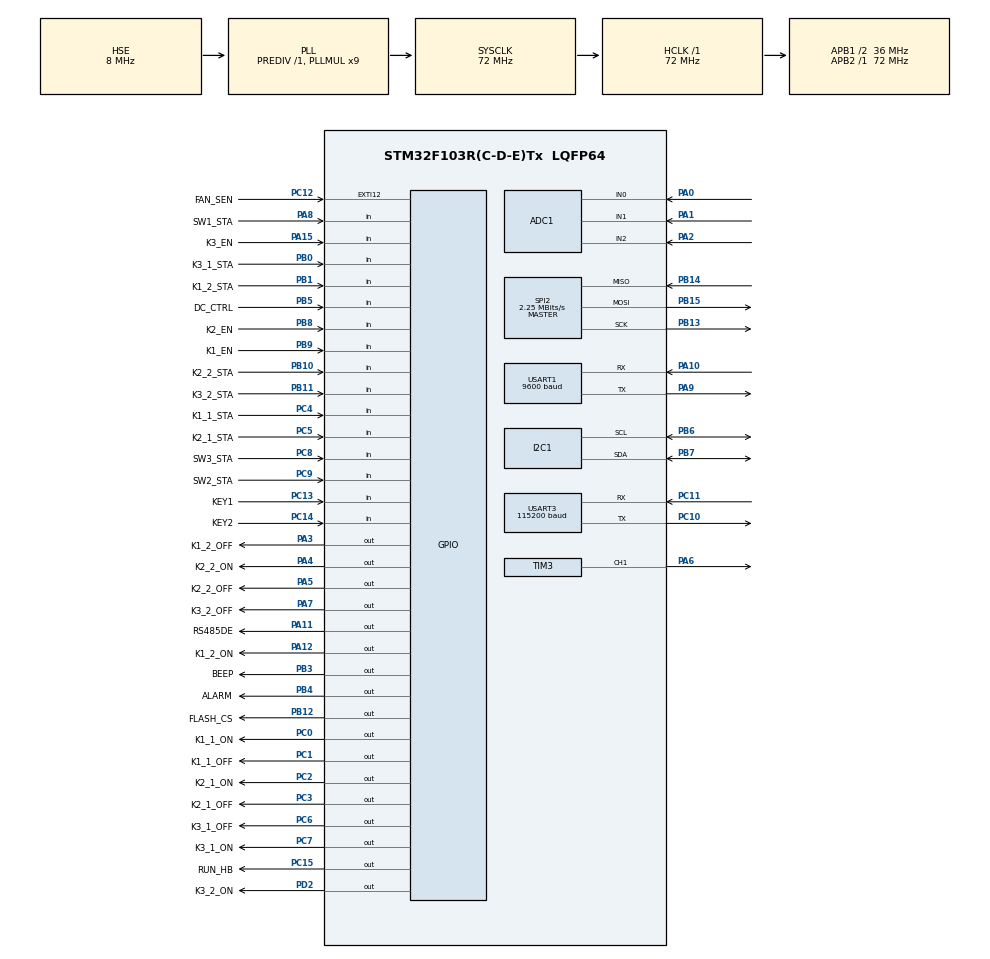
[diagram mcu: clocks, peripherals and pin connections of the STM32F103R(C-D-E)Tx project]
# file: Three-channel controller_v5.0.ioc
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ADC1.Channel-1\#ChannelRegularConversion=ADC_CHANNEL_1
ADC1.Channel-2\#ChannelRegularConversion=ADC_CHANNEL_2
ADC1.ContinuousConvMode=ENABLE
ADC1.DiscontinuousConvMode=DISABLE
ADC1.NbrOfConversion=3
ADC1.NbrOfConversionFlag=1
ADC1.Rank-1\#ChannelRegularConversion=2
ADC1.Rank-2\#ChannelRegularConversion=3
ADC1.SamplingTime-0\#ChannelRegularConversion=ADC_SAMPLETIME_55CYCLES_5
ADC1.SamplingTime-1\#ChannelRegularConversion=ADC_SAMPLETIME_55CYCLES_5
ADC1.SamplingTime-2\#ChannelRegularConversion=ADC_SAMPLETIME_55CYCLES_5
ADC1.master=1
Dma.ADC1.0.Direction=DMA_PERIPH_TO_MEMORY
Dma.ADC1.0.Instance=DMA1_Channel1
Dma.ADC1.0.MemDataAlignment=DMA_MDATAALIGN_HALFWORD
Dma.ADC1.0.MemInc=DMA_MINC_ENABLE
Dma.ADC1.0.Mode=DMA_CIRCULAR
Dma.ADC1.0.PeriphDataAlignment=DMA_PDATAALIGN_HALFWORD
Dma.ADC1.0.PeriphInc=DMA_PINC_DISABLE
Dma.ADC1.0.Priority=DMA_PRIORITY_LOW
Dma.Request0=ADC1
Mcu.Family=STM32F1
Mcu.Name=STM32F103R(C-D-E)Tx
Mcu.Package=LQFP64
NVIC.ADC1_2_IRQn=true\:5\:0\:true\:false\:true\:true\:true\:true
NVIC.EXTI15_10_IRQn=true\:4\:0\:true\:false\:true\:true\:true\:true
NVIC.PriorityGroup=NVIC_PRIORITYGROUP_4
PA0-WKUP.GPIO_Mode=GPIO_MODE_ANALOG
PA0-WKUP.Signal=ADCx_IN0
PA1.GPIO_Mode=GPIO_MODE_ANALOG
PA1.Signal=ADCx_IN1
PA10.Mode=Asynchronous
PA10.Signal=USART1_RX
PA11.GPIO_Label=RS485DE
PA11.GPIO_PuPd=GPIO_PULLDOWN
PA11.GPIO_Speed=GPIO_SPEED_FREQ_HIGH
PA11.PinState=GPIO_PIN_RESET
PA11.Signal=GPIO_Output
PA12.GPIO_Label=K1_2_ON
PA12.GPIO_PuPd=GPIO_PULLUP
PA12.GPIO_Speed=GPIO_SPEED_FREQ_HIGH
PA12.PinState=GPIO_PIN_SET
PA12.Signal=GPIO_Output
PA13.Mode=Serial_Wire
PA13.Signal=SYS_JTMS-SWDIO
PA14.Mode=Serial_Wire
PA14.Signal=SYS_JTCK-SWCLK
PA15.GPIO_Label=K3_EN
PA15.GPIO_PuPd=GPIO_PULLUP
PA15.Signal=GPIO_Input
PA2.GPIO_Mode=GPIO_MODE_ANALOG
PA2.Signal=ADCx_IN2
PA3.GPIO_Label=K1_2_OFF
PA3.GPIO_PuPd=GPIO_PULLUP
PA3.GPIO_Speed=GPIO_SPEED_FREQ_HIGH
PA3.PinState=GPIO_PIN_SET
PA3.Signal=GPIO_Output
PA4.GPIO_Label=K2_2_ON
PA4.GPIO_PuPd=GPIO_PULLUP
PA4.GPIO_Speed=GPIO_SPEED_FREQ_HIGH
PA4.PinState=GPIO_PIN_SET
PA4.Signal=GPIO_Output
PA5.GPIO_Label=K2_2_OFF
PA5.GPIO_PuPd=GPIO_PULLUP
PA5.GPIO_Speed=GPIO_SPEED_FREQ_HIGH
PA5.PinState=GPIO_PIN_SET
PA5.Signal=GPIO_Output
PA6.Signal=S_TIM3_CH1
PA7.GPIO_Label=K3_2_OFF
PA7.GPIO_PuPd=GPIO_PULLUP
PA7.GPIO_Speed=GPIO_SPEED_FREQ_HIGH
PA7.PinState=GPIO_PIN_SET
PA7.Signal=GPIO_Output
PA8.GPIO_Label=SW1_STA
PA8.GPIO_PuPd=GPIO_PULLDOWN
PA8.Signal=GPIO_Input
PA9.Mode=Asynchronous
PA9.Signal=USART1_TX
PB0.GPIO_Label=K3_1_STA
PB0.GPIO_PuPd=GPIO_PULLDOWN
PB0.Signal=GPIO_Input
PB1.GPIO_Label=K1_2_STA
PB1.GPIO_PuPd=GPIO_PULLDOWN
PB1.Signal=GPIO_Input
PB10.GPIO_Label=K2_2_STA
PB10.GPIO_PuPd=GPIO_PULLDOWN
PB10.Signal=GPIO_Input
PB11.GPIO_Label=K3_2_STA
PB11.GPIO_PuPd=GPIO_PULLDOWN
PB11.Signal=GPIO_Input
PB12.GPIO_Label=FLASH_CS
PB12.GPIO_PuPd=GPIO_NOPULL
PB12.GPIO_Speed=GPIO_SPEED_FREQ_HIGH
PB12.PinState=GPIO_PIN_SET
PB12.Signal=GPIO_Output
PB13.Mode=Full_Duplex_Master
PB13.Signal=SPI2_SCK
PB14.Mode=Full_Duplex_Master
PB14.Signal=SPI2_MISO
PB15.Mode=Full_Duplex_Master
PB15.Signal=SPI2_MOSI
PB3.GPIO_Label=BEEP
PB3.GPIO_PuPd=GPIO_PULLUP
PB3.GPIO_Speed=GPIO_SPEED_FREQ_HIGH
PB3.PinState=GPIO_PIN_SET
PB3.Signal=GPIO_Output
PB4.GPIO_Label=ALARM
PB4.GPIO_PuPd=GPIO_PULLUP
PB4.GPIO_Speed=GPIO_SPEED_FREQ_HIGH
PB4.PinState=GPIO_PIN_SET
PB4.Signal=GPIO_Output
PB5.GPIO_Label=DC_CTRL
PB5.GPIO_PuPd=GPIO_PULLUP
PB5.Signal=GPIO_Input
PB6.Mode=I2C
PB6.Signal=I2C1_SCL
PB7.Mode=I2C
PB7.Signal=I2C1_SDA
PB8.GPIO_Label=K2_EN
PB8.GPIO_PuPd=GPIO_PULLUP
PB8.Signal=GPIO_Input
PB9.GPIO_Label=K1_EN
PB9.GPIO_PuPd=GPIO_PULLUP
PB9.Signal=GPIO_Input
PC0.GPIO_Label=K1_1_ON
PC0.GPIO_PuPd=GPIO_PULLUP
PC0.GPIO_Speed=GPIO_SPEED_FREQ_HIGH
PC0.PinState=GPIO_PIN_SET
PC0.Signal=GPIO_Output
PC1.GPIO_Label=K1_1_OFF
PC1.GPIO_PuPd=GPIO_PULLUP
PC1.GPIO_Speed=GPIO_SPEED_FREQ_HIGH
PC1.PinState=GPIO_PIN_SET
PC1.Signal=GPIO_Output
PC10.Mode=Asynchronous
PC10.Signal=USART3_TX
PC11.Mode=Asynchronous
PC11.Signal=USART3_RX
PC12.GPIO_Label=FAN_SEN
PC12.GPIO_ModeDefaultEXTI=GPIO_MODE_IT_FALLING
PC12.GPIO_PuPd=GPIO_PULLUP
PC12.Signal=GPXTI12
PC13-TAMPER-RTC.GPIO_Label=KEY1
PC13-TAMPER-RTC.GPIO_PuPd=GPIO_PULLUP
PC13-TAMPER-RTC.Signal=GPIO_Input
PC14-OSC32_IN.GPIO_Label=KEY2
PC14-OSC32_IN.GPIO_PuPd=GPIO_PULLUP
PC14-OSC32_IN.Signal=GPIO_Input
PC15-OSC32_OUT.GPIO_Label=RUN_HB
PC15-OSC32_OUT.GPIO_PuPd=GPIO_NOPULL
PC15-OSC32_OUT.GPIO_Speed=GPIO_SPEED_FREQ_LOW
PC15-OSC32_OUT.PinState=GPIO_PIN_RESET
PC15-OSC32_OUT.Signal=GPIO_Output
PC2.GPIO_Label=K2_1_ON
PC2.GPIO_PuPd=GPIO_PULLUP
PC2.GPIO_Speed=GPIO_SPEED_FREQ_HIGH
PC2.PinState=GPIO_PIN_SET
PC2.Signal=GPIO_Output
PC3.GPIO_Label=K2_1_OFF
PC3.GPIO_PuPd=GPIO_PULLUP
PC3.GPIO_Speed=GPIO_SPEED_FREQ_HIGH
PC3.PinState=GPIO_PIN_SET
PC3.Signal=GPIO_Output
PC4.GPIO_Label=K1_1_STA
PC4.GPIO_PuPd=GPIO_PULLDOWN
PC4.Signal=GPIO_Input
PC5.GPIO_Label=K2_1_STA
PC5.GPIO_PuPd=GPIO_PULLDOWN
PC5.Signal=GPIO_Input
PC6.GPIO_Label=K3_1_OFF
PC6.GPIO_PuPd=GPIO_PULLUP
PC6.GPIO_Speed=GPIO_SPEED_FREQ_HIGH
PC6.PinState=GPIO_PIN_SET
PC6.Signal=GPIO_Output
PC7.GPIO_Label=K3_1_ON
PC7.GPIO_PuPd=GPIO_PULLUP
PC7.GPIO_Speed=GPIO_SPEED_FREQ_HIGH
PC7.PinState=GPIO_PIN_SET
PC7.Signal=GPIO_Output
PC8.GPIO_Label=SW3_STA
PC8.GPIO_PuPd=GPIO_PULLDOWN
PC8.Signal=GPIO_Input
PC9.GPIO_Label=SW2_STA
PC9.GPIO_PuPd=GPIO_PULLDOWN
PC9.Signal=GPIO_Input
PD0-OSC_IN.Mode=HSE-External-Oscillator
PD0-OSC_IN.Signal=RCC_OSC_IN
PD1-OSC_OUT.Mode=HSE-External-Oscillator
PD1-OSC_OUT.Signal=RCC_OSC_OUT
PD2.GPIO_Label=K3_2_ON
PD2.GPIO_PuPd=GPIO_PULLUP
PD2.GPIO_Speed=GPIO_SPEED_FREQ_HIGH
PD2.PinState=GPIO_PIN_SET
PD2.Signal=GPIO_Output
ProjectManager.HeapSize=0x200
ProjectManager.StackSize=0x400
ProjectManager.TargetToolchain=MDK-ARM V5.32
RCC.ADCPresc=RCC_ADCPCLK2_DIV6
RCC.AHBFreq_Value=72000000
RCC.APB1CLKDivider=RCC_HCLK_DIV2
RCC.APB1Freq_Value=36000000
RCC.APB1TimFreq_Value=72000000
RCC.APB2Freq_Value=72000000
RCC.APB2TimFreq_Value=72000000
RCC.HCLKFreq_Value=72000000
RCC.PLLMUL=RCC_PLL_MUL9
RCC.PLLSourceVirtual=RCC_PLLSOURCE_HSE
RCC.SYSCLKFreq_VALUE=72000000
RCC.SYSCLKSource=RCC_SYSCLKSOURCE_PLLCLK
RCC.USBFreq_Value=72000000
SH.ADCx_IN0.0=ADC1_IN0,IN0
SH.ADCx_IN1.0=ADC1_IN1,IN1
SH.ADCx_IN2.0=ADC1_IN2,IN2
SH.S_TIM3_CH1.0=TIM3_CH1,PWM Generation1 CH1
SPI2.BaudRatePrescaler=SPI_BAUDRATEPRESCALER_16
SPI2.CalculateBaudRate=2.25 MBits/s
SPI2.Direction=SPI_DIRECTION_2LINES
SPI2.Mode=SPI_MODE_MASTER
SPI2.VirtualNSS=VM_NSSSOFT
SPI2.VirtualType=VM_MASTER
TIM3.AutoReloadPreload=TIM_AUTORELOAD_PRELOAD_ENABLE
TIM3.Channel-PWM\ Generation1\ CH1=TIM_CHANNEL_1
TIM3.CounterMode=TIM_COUNTERMODE_UP
TIM3.Period=99
TIM3.Prescaler=35
TIM3.Pulse-PWM\ Generation1\ CH1=50
USART1.BaudRate=9600
USART1.VirtualMode=VM_ASYNC
USART3.BaudRate=115200
USART3.VirtualMode=VM_ASYNC
VP_TIM3_VS_ClockSourceINT.Mode=Internal
board=custom

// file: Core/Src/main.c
/* USER CODE BEGIN Header */
/**
  ******************************************************************************
  * @file           : main.c
  * @brief          : Main program body
  ******************************************************************************
  * @attention
  *
  * Copyright (c) 2026 STMicroelectronics.
  * All rights reserved.
  *
  * This software is licensed under terms that can be found in the LICENSE file
  * in the root directory of this software component.
  * If no LICENSE file comes with this software, it is provided AS-IS.
  *
  ******************************************************************************
  */
/* USER CODE END Header */
#include "main.h"
#include "adc.h"
#include "dma.h"
#include "i2c.h"
#include "spi.h"
#include "tim.h"
#include "usart.h"
#include "gpio.h"

/* USER CODE BEGIN Includes */
#include "app_controller.h"
#include "board_io.h"

/* USER CODE END Includes */

/* USER CODE BEGIN PV */
static uint32_t g_run_heartbeat_last_toggle_ms;
static uint8_t g_run_heartbeat_level;

/* USER CODE END PV */

void SystemClock_Config(void);

/* USER CODE BEGIN 0 */
static void Main_UpdateRunHeartbeat(uint32_t tick_ms)
{
  if ((tick_ms - g_run_heartbeat_last_toggle_ms) >= 50U)
  {
    g_run_heartbeat_last_toggle_ms = tick_ms;
    g_run_heartbeat_level = (g_run_heartbeat_level == 0U) ? 1U : 0U;
    BoardIO_SetRunHeartbeatOutput(g_run_heartbeat_level);
  }
}

/* USER CODE END 0 */

int main(void)
{

  /* MCU Configuration--------------------------------------------------------*/

  /* Reset of all peripherals, Initializes the Flash interface and the Systick. */
  HAL_Init();

  /* Configure the system clock */
  SystemClock_Config();

  /* Initialize all configured peripherals */
  MX_GPIO_Init();
  MX_DMA_Init();
  MX_ADC1_Init();
  MX_I2C1_Init();
  MX_SPI2_Init();
  MX_TIM3_Init();
  MX_USART1_UART_Init();
  MX_USART3_UART_Init();
  /* USER CODE BEGIN 2 */
  BoardIO_Init();
  AppController_Init(HAL_GetTick());

  /* USER CODE END 2 */

  /* Infinite loop */
  while (1)
  {

    /* USER CODE BEGIN 3 */
    uint32_t tick_ms = HAL_GetTick();

    AppController_RunOnce(tick_ms);
    Main_UpdateRunHeartbeat(tick_ms);
  }
  /* USER CODE END 3 */
}

void SystemClock_Config(void)
{
  RCC_OscInitTypeDef RCC_OscInitStruct = {0};
  RCC_ClkInitTypeDef RCC_ClkInitStruct = {0};
  RCC_PeriphCLKInitTypeDef PeriphClkInit = {0};

  /** Initializes the RCC Oscillators according to the specified parameters
  * in the RCC_OscInitTypeDef structure.
  */
  RCC_OscInitStruct.OscillatorType = RCC_OSCILLATORTYPE_HSE;
  RCC_OscInitStruct.HSEState = RCC_HSE_ON;
  RCC_OscInitStruct.HSEPredivValue = RCC_HSE_PREDIV_DIV1;
  RCC_OscInitStruct.HSIState = RCC_HSI_ON;
  RCC_OscInitStruct.PLL.PLLState = RCC_PLL_ON;
  RCC_OscInitStruct.PLL.PLLSource = RCC_PLLSOURCE_HSE;
  RCC_OscInitStruct.PLL.PLLMUL = RCC_PLL_MUL9;
  if (HAL_RCC_OscConfig(&RCC_OscInitStruct) != HAL_OK)
  {
    Error_Handler();
  }

  /** Initializes the CPU, AHB and APB buses clocks
  */
  RCC_ClkInitStruct.ClockType = RCC_CLOCKTYPE_HCLK|RCC_CLOCKTYPE_SYSCLK
                              |RCC_CLOCKTYPE_PCLK1|RCC_CLOCKTYPE_PCLK2;
  RCC_ClkInitStruct.SYSCLKSource = RCC_SYSCLKSOURCE_PLLCLK;
  RCC_ClkInitStruct.AHBCLKDivider = RCC_SYSCLK_DIV1;
  RCC_ClkInitStruct.APB1CLKDivider = RCC_HCLK_DIV2;
  RCC_ClkInitStruct.APB2CLKDivider = RCC_HCLK_DIV1;

  if (HAL_RCC_ClockConfig(&RCC_ClkInitStruct, FLASH_LATENCY_2) != HAL_OK)
  {
    Error_Handler();
  }
  PeriphClkInit.PeriphClockSelection = RCC_PERIPHCLK_ADC;
  PeriphClkInit.AdcClockSelection = RCC_ADCPCLK2_DIV6;
  if (HAL_RCCEx_PeriphCLKConfig(&PeriphClkInit) != HAL_OK)
  {
    Error_Handler();
  }
}

void Error_Handler(void)
{
  __disable_irq();
  while (1)
  {
  }
}
